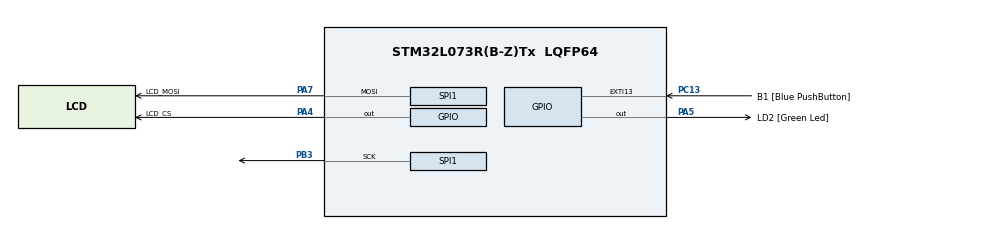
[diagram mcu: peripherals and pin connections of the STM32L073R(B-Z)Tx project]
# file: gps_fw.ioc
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Dma.Request0=SPI1_TX
Dma.SPI1_TX.0.Direction=DMA_MEMORY_TO_PERIPH
Dma.SPI1_TX.0.Instance=DMA1_Channel3
Dma.SPI1_TX.0.MemDataAlignment=DMA_MDATAALIGN_BYTE
Dma.SPI1_TX.0.MemInc=DMA_MINC_ENABLE
Dma.SPI1_TX.0.Mode=DMA_NORMAL
Dma.SPI1_TX.0.PeriphDataAlignment=DMA_PDATAALIGN_BYTE
Dma.SPI1_TX.0.PeriphInc=DMA_PINC_DISABLE
Dma.SPI1_TX.0.Priority=DMA_PRIORITY_LOW
Mcu.Family=STM32L0
Mcu.Name=STM32L073R(B-Z)Tx
Mcu.Package=LQFP64
NVIC.DMA1_Channel2_3_IRQn=true\:0\:0\:false\:false\:false\:false\:false
PA13.GPIO_Label=TMS
PA13.Mode=Serial_Wire
PA13.Signal=SYS_SWDIO
PA14.GPIO_Label=TCK
PA14.Mode=Serial_Wire
PA14.Signal=SYS_SWCLK
PA2.GPIO_Label=USART_TX
PA2.Signal=USART2_TX
PA3.GPIO_Label=USART_RX
PA3.Signal=USART2_RX
PA4.GPIO_Label=LCD_CS
PA4.Signal=GPIO_Output
PA5.GPIO_Label=LD2 [Green Led]
PA5.Signal=GPIO_Output
PA7.GPIO_Label=LCD_MOSI
PA7.Mode=TX_Only_Simplex_Unidirect_Master
PA7.Signal=SPI1_MOSI
PB3.Mode=TX_Only_Simplex_Unidirect_Master
PB3.Signal=SPI1_SCK
PC13.GPIO_Label=B1 [Blue PushButton]
PC13.GPIO_ModeDefaultEXTI=GPIO_MODE_IT_FALLING
PC13.Signal=GPXTI13
PC14-OSC32_IN.Signal=RCC_OSC32_IN
PC15-OSC32_OUT.Signal=RCC_OSC32_OUT
PH0-OSC_IN.GPIO_Label=MCO
PH0-OSC_IN.Signal=RCC_OSC_IN
ProjectManager.HeapSize=0x200
ProjectManager.StackSize=0x400
ProjectManager.TargetToolchain=SW4STM32
RCC.AHBFreq_Value=16000000
RCC.APB1Freq_Value=16000000
RCC.APB1TimFreq_Value=16000000
RCC.APB2Freq_Value=16000000
RCC.APB2TimFreq_Value=16000000
RCC.HCLKFreq_Value=16000000
RCC.HSE_VALUE=8000000
RCC.HSI16_VALUE=16000000
RCC.HSI48_VALUE=48000000
RCC.HSI_VALUE=16000000
RCC.LSEState=RCC_LSE_ON
RCC.LSE_VALUE=32768
RCC.MSI_VALUE=2097000
RCC.PLLMUL=RCC_PLLMUL_4
RCC.SYSCLKFreq_VALUE=16000000
RCC.SYSCLKSource=RCC_SYSCLKSOURCE_HSI
RCC.VCOOutputFreq_Value=64000000
SPI1.BaudRatePrescaler=SPI_BAUDRATEPRESCALER_32
SPI1.CalculateBaudRate=500.0 KBits/s
SPI1.Direction=SPI_DIRECTION_2LINES
SPI1.FirstBit=SPI_FIRSTBIT_LSB
SPI1.Mode=SPI_MODE_MASTER
SPI1.VirtualType=VM_MASTER
board=NUCLEO-L073RZ

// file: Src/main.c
/* USER CODE BEGIN Header */
/**
  ******************************************************************************
  * @file           : main.c
  * @brief          : Main program body
  ******************************************************************************
  * @attention
  *
  * <h2><center>&copy; Copyright (c) 2019 STMicroelectronics.
  * All rights reserved.</center></h2>
  *
  * This software component is licensed by ST under BSD 3-Clause license,
  * the "License"; You may not use this file except in compliance with the
  * License. You may obtain a copy of the License at:
  *                        opensource.org/licenses/BSD-3-Clause
  *
  ******************************************************************************
  */
/* USER CODE END Header */

#include "main.h"
#include "dma.h"
#include "spi.h"
#include "gpio.h"

/* USER CODE BEGIN Includes */

#include "../Modules/Lcd/lcd_driver.h"
#include "../Tools/my_assert.h"
#include "../Tools/sw_timer.h"

/* USER CODE END Includes */

void SystemClock_Config(void);

int main(void)
{

  /* MCU Configuration--------------------------------------------------------*/

  /* Reset of all peripherals, Initializes the Flash interface and the Systick. */

  LL_APB2_GRP1_EnableClock(LL_APB2_GRP1_PERIPH_SYSCFG);
  LL_APB1_GRP1_EnableClock(LL_APB1_GRP1_PERIPH_PWR);

  /* System interrupt init*/

  /* Configure the system clock */
  SystemClock_Config();

  /* Initialize all configured peripherals */
  MX_GPIO_Init();
  MX_DMA_Init();
  MX_SPI1_Init();
  /* USER CODE BEGIN 2 */

  sw_timer_init();
  lcd_driver_init();

  /* USER CODE END 2 */

  /* Infinite loop */
  /* USER CODE BEGIN WHILE */
  while (1)
  {
      sw_timer_process();
      lcd_driver_process();
    /* USER CODE END WHILE */

  }
}

void SystemClock_Config(void)
{
  LL_FLASH_SetLatency(LL_FLASH_LATENCY_0);

  if(LL_FLASH_GetLatency() != LL_FLASH_LATENCY_0)
  {
  Error_Handler();
  }
  LL_PWR_SetRegulVoltageScaling(LL_PWR_REGU_VOLTAGE_SCALE1);
  LL_RCC_HSI_Enable();

   /* Wait till HSI is ready */
  while(LL_RCC_HSI_IsReady() != 1)
  {

  }
  LL_RCC_HSI_SetCalibTrimming(16);
  LL_RCC_SetAHBPrescaler(LL_RCC_SYSCLK_DIV_1);
  LL_RCC_SetAPB1Prescaler(LL_RCC_APB1_DIV_1);
  LL_RCC_SetAPB2Prescaler(LL_RCC_APB2_DIV_1);
  LL_RCC_SetSysClkSource(LL_RCC_SYS_CLKSOURCE_HSI);

   /* Wait till System clock is ready */
  while(LL_RCC_GetSysClkSource() != LL_RCC_SYS_CLKSOURCE_STATUS_HSI)
  {

  }

  LL_Init1msTick(16000000);

  LL_SYSTICK_SetClkSource(LL_SYSTICK_CLKSOURCE_HCLK);
  LL_SetSystemCoreClock(16000000);
}

void Error_Handler(void)
{
}

/************************ (C) COPYRIGHT STMicroelectronics *****END OF FILE****/
